# STM32U5xx register map
File version: 1.3
Registers are 32-bit, read-write, reset 0x0 unless marked. A register's access mark holds for its fields unless they carry their own. Offsets are from the block's base; [hi:lo] are bit positions; {n}, {i} and the like mark numbered series.

## TIM6 — General-purpose-timers
Base 0x40001000
Same registers: TIM7 0x40001400, SEC_TIM6 0x50001000, SEC_TIM7 0x50001400
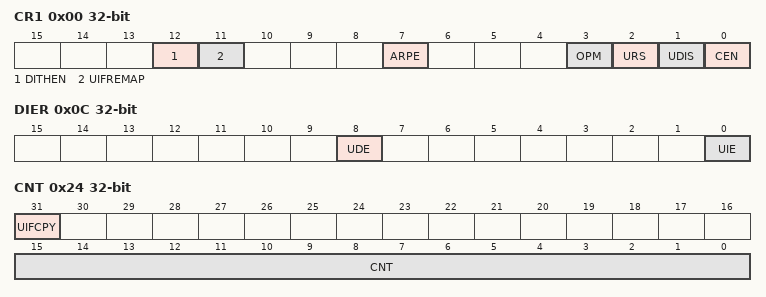
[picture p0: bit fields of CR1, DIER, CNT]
0x00 CR1 — control register 1
  [12] DITHEN — Dithering Enable
  [11] UIFREMAP — UIF status bit remapping
  [7] ARPE — Auto-reload preload enable
  [3] OPM — One-pulse mode
  [2] URS — Update request source
  [1] UDIS — Update disable
  [0] CEN — Counter enable
0x04 CR2 — control register 2
  [6:4] MMS — Master mode selection
0x0C DIER — DMA/Interrupt enable register
  [8] UDE, [0] UIE
0x10 SR — status register
  [0] UIF
0x14 EGR wo — event generation register
  [0] UG
0x24 CNT — counter
  [31] UIFCPY, [15:0] CNT
0x28 PSC — prescaler
  [15:0] PSC
0x2C ARR reset 0xFFFF — auto-reload register
  [18:0] ARR

## WWDG — System window watchdog
Base 0x40002C00
Same registers: SEC_WWDG 0x50002C00
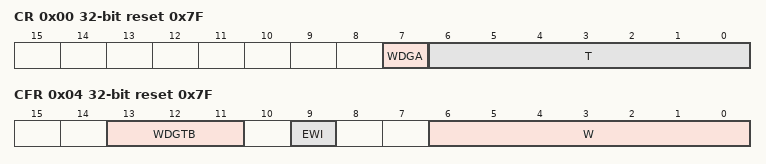
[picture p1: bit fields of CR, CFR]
0x00 CR reset 0x7F — Control register
  [7] WDGA — Activation bit
  [6:0] T — 7-bit counter (MSB to LSB)
0x04 CFR reset 0x7F — Configuration register
  [13:11] WDGTB — Timer base
  [9] EWI — Early wakeup interrupt
  [6:0] W — 7-bit window value
0x08 SR — Status register
  [0] EWIF — Early wakeup interrupt flag

## SYSCFG — System configuration controller
Base 0x46000400
Same registers: SEC_SYSCFG 0x56000400
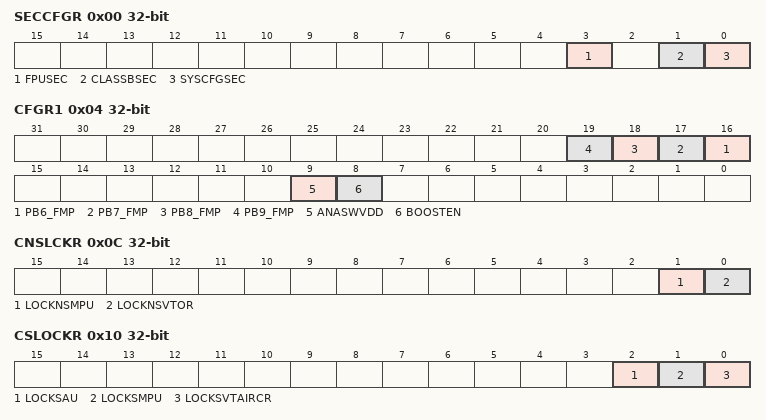
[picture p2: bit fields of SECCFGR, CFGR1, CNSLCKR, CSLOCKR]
0x00 SECCFGR — SYSCFG secure configuration register
  [3] FPUSEC
  [1] CLASSBSEC
  [0] SYSCFGSEC — SYSCFG clock control security
0x04 CFGR1 — configuration register 1
  [n+10] PB{n}_FMP (n=6..9)
  [9] ANASWVDD — GPIO analog switch control voltage selection
  [8] BOOSTEN — I/O analog switch voltage booster enable
0x08 FPUIMR reset 0x1F — FPU interrupt mask register
  [5:0] FPU_IE — Floating point unit interrupts enable bits
0x0C CNSLCKR — SYSCFG CPU non-secure lock register
  [1] LOCKNSMPU — Non-secure MPU registers lock
  [0] LOCKNSVTOR — VTOR_NS register lock
0x10 CSLOCKR — SYSCFG CPU secure lock register
  [2] LOCKSAU, [1] LOCKSMPU, [0] LOCKSVTAIRCR
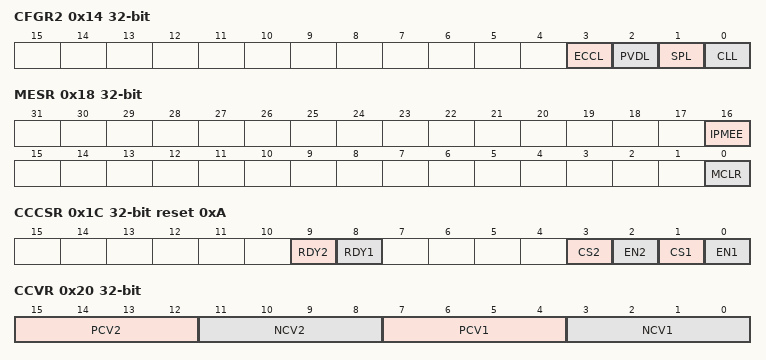
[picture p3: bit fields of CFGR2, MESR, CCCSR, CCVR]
0x14 CFGR2 — configuration register 2
  [3] ECCL — ECC Lock
  [2] PVDL — PVD lock enable bit
  [1] SPL — SRAM ECC lock bit
  [0] CLL — LOCKUP (hardfault) output enable bit
0x18 MESR — memory erase status register
  [16] IPMEE, [0] MCLR
0x1C CCCSR access per field reset 0xA — compensation cell control/status register
  [9] RDY2 ro, [8] RDY1 ro, [3] CS2 rw, [2] EN2 rw, [1] CS1 rw, [0] EN1 rw
0x20 CCVR ro — compensation cell value register
  [15:12] PCV2, [11:8] NCV2, [7:4] PCV1, [3:0] NCV1
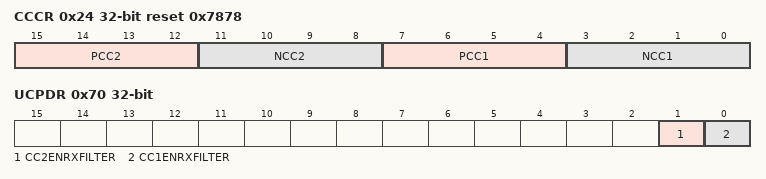
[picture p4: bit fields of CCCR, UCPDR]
0x24 CCCR reset 0x7878 — compensation cell code register
  [15:12] PCC2, [11:8] NCC2, [7:4] PCC1, [3:0] NCC1
0x2C RSSCMDR — RSS command register
  [15:0] RSSCMD — RSS commands
0x70 UCPDR — USB Type C and Power Delivery register
  [1] CC2ENRXFILTER, [0] CC1ENRXFILTER

## PKA — Private key accelerator
Base 0x420C2000
Same registers: SEC_PKA 0x520C2000
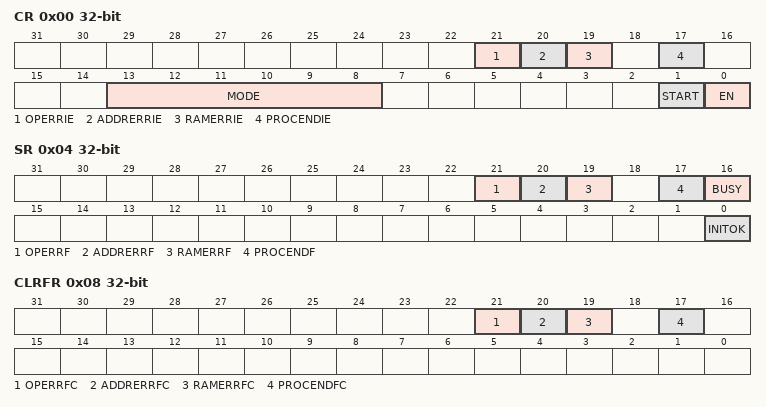
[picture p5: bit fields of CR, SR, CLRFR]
0x00 CR — Control register
  [21] OPERRIE — Operation error interrupt enable
  [20] ADDRERRIE — Address error interrupt enable
  [19] RAMERRIE — RAM error interrupt enable
  [17] PROCENDIE — End of operation interrupt enable
  [13:8] MODE — PKA Operation Mode
  [1] START — Start the operation
  [0] EN — Peripheral Enable
0x04 SR ro — PKA status register
  [21] OPERRF
  [20] ADDRERRF
  [19] RAMERRF
  [17] PROCENDF — PKA End of Operation flag
  [16] BUSY — PKA operation is in progress
  [0] INITOK
0x08 CLRFR wo — PKA clear flag register
  [21] OPERRFC
  [20] ADDRERRFC
  [19] RAMERRFC
  [17] PROCENDFC — Clear PKA End of Operation flag

## DBGMCU — MCU debug component
Base 0xE0044000
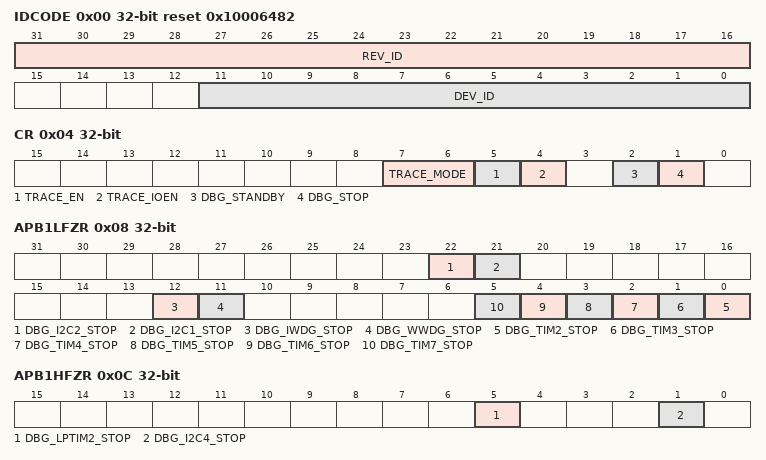
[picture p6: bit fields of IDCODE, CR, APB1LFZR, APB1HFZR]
0x00 IDCODE ro reset 0x10006482 — DBGMCU_IDCODE
  [31:16] REV_ID — Revision
  [11:0] DEV_ID — Device dentification
0x04 CR — Debug MCU configuration register
  [7:6] TRACE_MODE — Trace pin assignment control
  [5] TRACE_EN — trace port and clock enable
  [4] TRACE_IOEN — Trace pin assignment control
  [2] DBG_STANDBY — Debug Standby mode
  [1] DBG_STOP — Debug Stop mode
0x08 APB1LFZR — Debug MCU APB1L peripheral freeze register
  [22] DBG_I2C2_STOP — I2C2 SMBUS timeout stop in debug
  [21] DBG_I2C1_STOP — I2C1 SMBUS timeout stop in debug
  [12] DBG_IWDG_STOP — Independent watchdog counter stop in debug
  [11] DBG_WWDG_STOP — Window watchdog counter stop in debug
  [n-2] DBG_TIM{n}_STOP (n=2..7) — TIM{n} stop in debug
0x0C APB1HFZR — Debug MCU APB1H peripheral freeze register
  [5] DBG_LPTIM2_STOP — LPTIM2 stop in debug
  [1] DBG_I2C4_STOP — I2C4 stop in debug
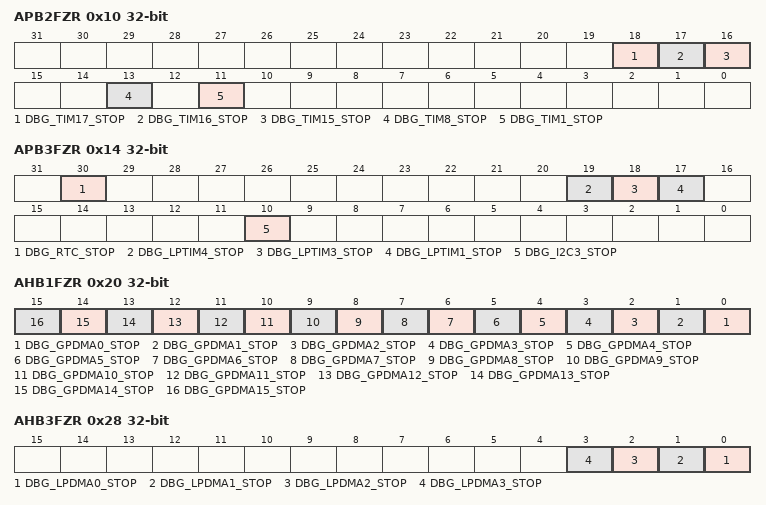
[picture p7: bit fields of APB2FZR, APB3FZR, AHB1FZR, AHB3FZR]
0x10 APB2FZR — Debug MCU APB2 peripheral freeze register
  [18] DBG_TIM17_STOP
  [17] DBG_TIM16_STOP — TIM16 counter stopped when core is halted
  [16] DBG_TIM15_STOP — TIM15 counter stopped when core is halted
  [13] DBG_TIM8_STOP — TIM8 stop in debug
  [11] DBG_TIM1_STOP — TIM1 counter stopped when core is halted
0x14 APB3FZR — Debug MCU APB3 peripheral freeze register
  [30] DBG_RTC_STOP — RTC stop in debug
  [19] DBG_LPTIM4_STOP — LPTIM4 stop in debug
  [18] DBG_LPTIM3_STOP — LPTIM3 stop in debug
  [17] DBG_LPTIM1_STOP — LPTIM1 stop in debug
  [10] DBG_I2C3_STOP — I2C3 stop in debug
0x20 AHB1FZR — Debug MCU AHB1 peripheral freeze register
  [n] DBG_GPDMA{n}_STOP (n=0..15) — GPDMA channel {n} stop in debug
0x28 AHB3FZR — Debug MCU AHB3 peripheral freeze register
  [n] DBG_LPDMA{n}_STOP (n=0..3) — LPDMA channel {n} stop in debug
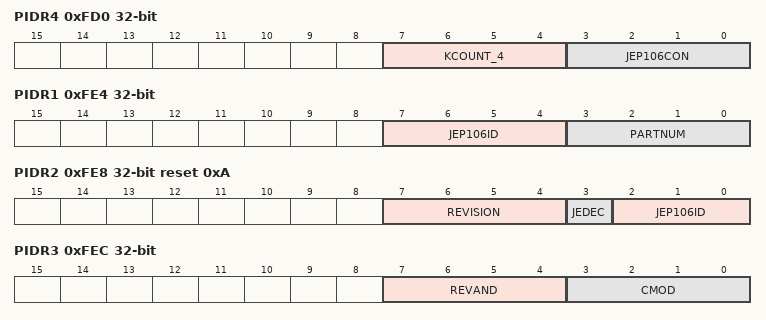
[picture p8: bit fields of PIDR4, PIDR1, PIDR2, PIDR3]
0xFD0 PIDR4 ro — Debug MCU CoreSight peripheral identity register 4
  [7:4] KCOUNT_4 — register file size
  [3:0] JEP106CON — JEP106 continuation code
0xFE0 PIDR0 ro — Debug MCU CoreSight peripheral identity register 0
  [7:0] PARTNUM — part number bits [7:0]
0xFE4 PIDR1 ro — Debug MCU CoreSight peripheral identity register 1
  [7:4] JEP106ID — JEP106 identity code bits [3:0]
  [3:0] PARTNUM — part number bits [11:8]
0xFE8 PIDR2 ro reset 0xA — Debug MCU CoreSight peripheral identity register 2
  [7:4] REVISION — component revision number
  [3] JEDEC — JEDEC assigned value
  [2:0] JEP106ID — JEP106 identity code bits [6:4]
0xFEC PIDR3 ro — Debug MCU CoreSight peripheral identity register 3
  [7:4] REVAND — metal fix version
  [3:0] CMOD — customer modified
0xFF0 CIDR0 ro reset 0xD — Debug MCU CoreSight component identity register 0
  [7:0] PREAMBLE — component identification bits [7:0]
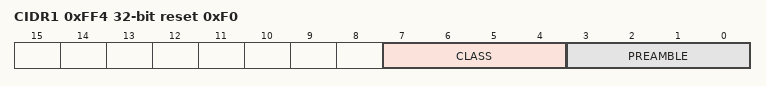
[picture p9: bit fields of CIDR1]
0xFF4 CIDR1 ro reset 0xF0 — Debug MCU CoreSight component identity register 1
  [7:4] CLASS — component identification bits [15:12] - component class
  [3:0] PREAMBLE — component identification bits [11:8]
0xFF8 CIDR2 ro reset 0x5 — Debug MCU CoreSight component identity register 2
  [7:0] PREAMBLE — component identification bits [23:16]
0xFFC CIDR3 ro reset 0xB1 — Debug MCU CoreSight component identity register 3
  [7:0] PREAMBLE — component identification bits [31:24]
